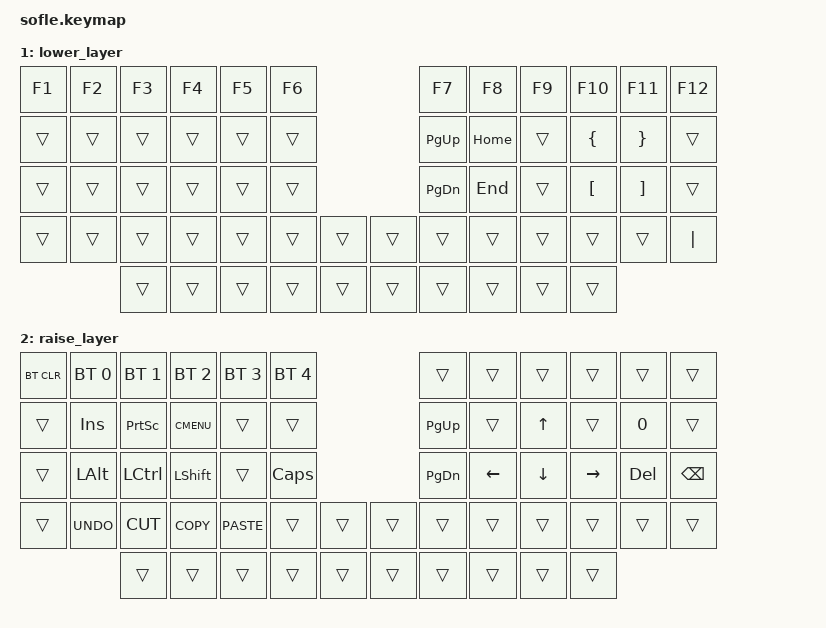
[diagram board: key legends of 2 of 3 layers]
/*
 * Copyright (c) 2020 The ZMK Contributors
 *
 * SPDX-License-Identifier: MIT
 */

#include <behaviors.dtsi>
#include <dt-bindings/zmk/keys.h>
#include <dt-bindings/zmk/bt.h>

/ {
    keymap {
        compatible = "zmk,keymap";

        default_layer {
// ------------------------------------------------------------------------------------------------------------
// |  `    |  1  |  2  |  3   |  4   |  5   |                   |  6   |  7    |  8    |  9   |   0   | BSPC  |
// |  ESC  |  Q  |  W  |  E   |  R   |  T   |                   |  Y   |  U    |  I    |  O   |   P   |  DEL  |
// | TAB   |  A  |  S  |  D   |  F   |  G   |                   |  H   |  J    |  K    |  L   |   ;   |   '   |
// | SHIFT |  Z  |  X  |  C   |  V   |  B   |  MUTE  |  |  PSCR |  N   |  M    |  ,    |  .   |   /   |  #    |
//               | CTRL| ALT  | GUI  | LGUI | SPACE  |  | ENTER |   <- |  ^    |   v   |  ->  |
            bindings = <
&kp GRAVE &kp N1 &kp N2   &kp N3   &kp N4    &kp N5                       &kp N6    &kp N7    &kp N8    &kp N9   &kp N0   &kp BSPC
&kp ESC   &kp Q  &kp W    &kp E    &kp R     &kp T                        &kp Y     &kp U     &kp I     &kp O    &kp P    &kp DEL
&kp TAB   &kp A  &kp S    &kp D    &kp F     &kp G                        &kp H     &kp J     &kp K     &kp L    &kp SEMI &kp SQT
&kp LSHFT &kp Z  &kp X    &kp C    &kp V     &kp B  &kp C_MUTE  &kp PSCRN &kp N     &kp M     &kp COMMA &kp DOT  &kp FSLH &kp HASH 
                 &kp LCTR &kp LALT &kp LGUI  &kp SPACE          &kp RET   &kp LEFT  &kp UP    &kp DOWN  &kp RIGHT 
            >;

            sensor-bindings = <&inc_dec_kp C_VOL_UP C_VOL_DN &inc_dec_kp PG_UP PG_DN>;
        };

        lower_layer {
// TODO: Some binds are waiting for shifted keycode support.
// ------------------------------------------------------------------------------------------------------------
// |  F1   |  F2 |  F3  |  F4 |  F5  |  F6  |                   |  F7  |  F8   |  F9   |  F10 |  F11  |  F12  |
// |       |     |      |     |      |      |                   | PGUP | HOME  |       |  {   |  }    |       |
// |       |     |      |     |      |      |                   | PGDN | END   |       |  [   |  ]    |       |
// |       |     |      |     |      |      |        |  |       |      |       |       |      |       |  |    |
//               |      |     |      |      |        |  |       |      |       |       |      |
            bindings = <
&kp F1    &kp F2    &kp F3    &kp F4  &kp F5    &kp F6                     &kp F7    &kp F8    &kp F9    &kp F10   &kp F11   &kp F12
&trans    &trans    &trans    &trans  &trans   &trans                      &kp PG_UP &kp HOME  &trans    &kp LBRC  &kp RBRC  &trans
&trans    &trans    &trans    &trans  &trans   &trans                      &kp PG_DN &kp END   &trans    &kp LBKT  &kp RBKT  &trans
&trans    &trans    &trans    &trans  &trans   &trans    &trans   &trans   &trans    &trans    &trans    &trans    &trans    &kp PIPE    
                    &trans    &trans  &trans   &trans    &trans   &trans   &trans    &trans    &trans    &trans
            >;

            sensor-bindings = <&inc_dec_kp C_VOL_UP C_VOL_DN &inc_dec_kp PG_UP PG_DN>;
        };

        raise_layer {
// ------------------------------------------------------------------------------------------------------------
// |BTCLR| BT1  | BT2  |  BT3  |  BT4  |  BT5 |                |      |      |       |      |       |       |
// |     | INS  | PSCR | GUI   |       |      |                | PGUP |      |   ^   |      |       |       |
// |     | ALT  | CTRL | SHIFT |       | CAPS |                | PGDN |   <- |   v   |  ->  |  DEL  | BKSPC |
// |     | UNDO | CUT  | COPY  | PASTE |      |      |  |      |      |      |       |      |       |       |
//              |      |       |       |      |      |  |      |      |      |       |      |
            bindings = <
&bt BT_CLR &bt BT_SEL 0 &bt BT_SEL 1 &bt BT_SEL 2 &bt BT_SEL 3 &bt BT_SEL 4             &trans    &trans    &trans   &trans    &trans  &trans
&trans     &kp INS      &kp PSCRN    &kp K_CMENU  &trans       &trans                   &kp PG_UP &trans    &kp UP   &trans    &kp N0  &trans
&trans     &kp LALT     &kp LCTRL    &kp LSHFT    &trans       &kp CLCK                 &kp PG_DN &kp LEFT  &kp DOWN &kp RIGHT &kp DEL &kp BSPC
&trans     &kp K_UNDO   &kp K_CUT    &kp K_COPY   &kp K_PASTE  &trans  &trans   &trans  &trans    &trans    &trans   &trans    &trans  &trans
                        &trans       &trans       &trans       &trans  &trans   &trans  &trans    &trans    &trans   &trans
            >;

            sensor-bindings = <&inc_dec_kp C_VOL_UP C_VOL_DN &inc_dec_kp PG_UP PG_DN>;
        };
    };
};
